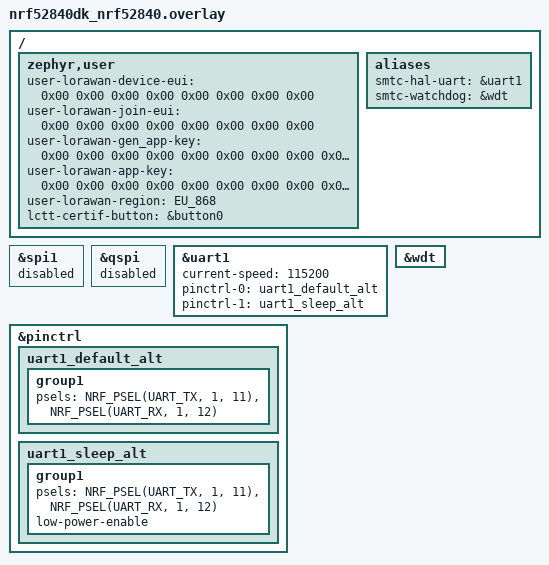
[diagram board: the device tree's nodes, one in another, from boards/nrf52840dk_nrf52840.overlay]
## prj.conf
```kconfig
# Copyright (c) 2024 Semtech Corporation - Félix Piédallu
# SPDX-License-Identifier: Apache-2.0

CONFIG_USE_SEGGER_RTT=n

# ------------------------------ General configuration -------------------------

# required for floorf (which is used within the smtc_modem lib)
CONFIG_NEWLIB_LIBC=y

# stack size (2048 required by Semtech)
CONFIG_MAIN_STACK_SIZE=4096
# some opereations will be triggered from the system workq, so match above stack size
CONFIG_SYSTEM_WORKQUEUE_STACK_SIZE=4096
# heap size
CONFIG_HEAP_MEM_POOL_SIZE=4096

CONFIG_LOG_BUFFER_SIZE=4096

CONFIG_LOG=y
CONFIG_LOG_BACKEND_UART=y

CONFIG_TEST_RANDOM_GENERATOR=y

CONFIG_SERIAL=y
CONFIG_UART_INTERRUPT_DRIVEN=y

# ------------------------------ Transceiver driver ----------------------------
CONFIG_LORA_BASICS_MODEM_DRIVERS=y
CONFIG_LORA_BASICS_MODEM_DRIVERS_EVENT_TRIGGER_GLOBAL_THREAD=y

# ------------------------------ Requirements LBM ------------------------------

CONFIG_SETTINGS=y
CONFIG_SETTINGS_NVS=y

CONFIG_NVS=y
CONFIG_FLASH=y
CONFIG_FLASH_MAP=y

CONFIG_REBOOT=y

# ------------------------------ LoRa Basics Modem -----------------------------

CONFIG_LORA_BASICS_MODEM=y

# FIXME: maybe use SETTINGS
CONFIG_LORA_BASICS_MODEM_USER_STORAGE_IMPL=n

CONFIG_LORA_BASICS_MODEM_RP2_103=y
CONFIG_LORA_BASICS_MODEM_ENABLE_ALL_REGIONS=y

CONFIG_LORA_BASICS_MODEM_CRYPTOGRAPHY_SOFT=n

CONFIG_LORA_BASICS_MODEM_CLASS_B=y
CONFIG_LORA_BASICS_MODEM_CLASS_C=y
CONFIG_LORA_BASICS_MODEM_MULTICAST=y
CONFIG_LORA_BASICS_MODEM_CSMA=y

CONFIG_LORA_BASICS_MODEM_ALC_SYNC=y
CONFIG_LORA_BASICS_MODEM_ALC_SYNC_V2=y

CONFIG_LORA_BASICS_MODEM_FUOTA=y
# CONFIG_LORA_BASICS_MODEM_FUOTA_V1=y
# CONFIG_LORA_BASICS_MODEM_FUOTA_FMP=y
# CONFIG_LORA_BASICS_MODEM_FUOTA_MPA=y

CONFIG_LORA_BASICS_MODEM_ALMANAC=y
CONFIG_LORA_BASICS_MODEM_STREAM=y
CONFIG_LORA_BASICS_MODEM_LFU=y
CONFIG_LORA_BASICS_MODEM_DEVICE_MANAGEMENT=y
CONFIG_LORA_BASICS_MODEM_GEOLOCATION=y
CONFIG_LORA_BASICS_MODEM_STORE_AND_FORWARD=y
# CONFIG_LORA_BASICS_MODEM_BEACON_TX=y
# CONFIG_LORA_BASICS_MODEM_RELAY_TX=y


CONFIG_LORA_BASICS_MODEM_APP_HELPERS=y

# Increase required for store_and_forward
CONFIG_LORA_BASICS_MODEM_CONTEXT_BUFFER_SIZE=1024


# ------------------------------ Debug ------------------------------

# Compiler optimizations will be set to -Og independently of other options.
CONFIG_DEBUG_OPTIMIZATIONS=y

# This option enables the addition of various information that can be
# used by debuggers in debugging the system, or enable additional debugging
# information to be reported at runtime.
CONFIG_DEBUG_INFO=y

# This option adds additional information to the thread object, so that the
# debugger can discover the threads.
CONFIG_DEBUG_THREAD_INFO=y
CONFIG_DEBUG_COREDUMP=y

# enable asserts during development only
CONFIG_ASSERT=y

CONFIG_LORA_BASICS_MODEM_LOG_LEVEL_DBG=y
CONFIG_LORA_BASICS_MODEM_LOG_LEVEL_DEEP_DBG=y

# ------------------------------ Requirements of this sample ------------------------------

CONFIG_PM_DEVICE=y
CONFIG_WATCHDOG=y
```

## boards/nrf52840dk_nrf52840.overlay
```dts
/*
 * Copyright (c) 2024 Semtech Corporation
 *
 * SPDX-License-Identifier: Apache-2.0
 */

/ {
	zephyr,user {
		user-lorawan-device-eui = <0x00 0x00 0x00 0x00 0x00 0x00 0x00 0x00>;
		user-lorawan-join-eui = <0x00 0x00 0x00 0x00 0x00 0x00 0x00 0x00>;
		user-lorawan-gen_app-key = <0x00 0x00 0x00 0x00 0x00 0x00 0x00 0x00 0x00 0x00 0x00 0x00 0x00 0x00 0x00 0x00>;
		user-lorawan-app-key = <0x00 0x00 0x00 0x00 0x00 0x00 0x00 0x00 0x00 0x00 0x00 0x00 0x00 0x00 0x00 0x00>;
		user-lorawan-region = "EU_868";

		/* PINS used for the sample. */
		lctt-certif-button = &button0;
	};

	aliases {
		/* Specify which UART is used as input for the hw modem tester */
		smtc-hal-uart = &uart1;
		smtc-watchdog = &wdt;
	};
};

&spi1 {
	status = "disabled";
};
// &spi2 {
//     status = "disabled";
// };
&qspi {
	status = "disabled";
};

/* Specify which UART is used as input for the hw modem tester */
&uart1 {
	status = "okay";

	current-speed = <115200>;

	pinctrl-0 = <&uart1_default_alt>;
	pinctrl-1 = <&uart1_sleep_alt>;
	pinctrl-names = "default", "sleep";
	/delete-property/ hw-flow-control;
};

&pinctrl {
	uart1_default_alt: uart1_default_alt {
		group1 {
			psels = <NRF_PSEL(UART_TX, 1, 11)>, <NRF_PSEL(UART_RX, 1, 12)>;
		};
	};

	uart1_sleep_alt: uart1_sleep_alt {
		group1 {
			psels = <NRF_PSEL(UART_TX, 1, 11)>, <NRF_PSEL(UART_RX, 1, 12)>;
			low-power-enable;
		};
	};
};

&wdt {
	status = "okay";
};
```

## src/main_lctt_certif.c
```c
/*
 * Copyright (c) 2024 Semtech Corporation
 *
 * SPDX-License-Identifier: Apache-2.0
 */

#include <zephyr/kernel.h>
#include <stdint.h>
#include <stdbool.h>

#include "smtc_modem_api.h"
#include "smtc_modem_utilities.h"

#include "smtc_modem_hal.h"
#include "smtc_hal_dbg_trace.h"

#include "smtc_hal_mcu.h"
#include "smtc_hal_gpio.h"
#include "smtc_hal_watchdog.h"
#include <smtc_modem_hal_init.h>

#include <string.h>
#include "smtc_modem_relay_api.h"

/*!
 * @brief Stringify constants
 */
#define xstr(a) str(a)
#define str(a)  #a

/*!
 * @brief Helper macro that returned a human-friendly message if a command does not return
 * SMTC_MODEM_RC_OK
 *
 * @remark The macro is implemented to be used with functions returning a @ref
 * smtc_modem_return_code_t
 *
 * @param[in] rc  Return code
 */

#define ASSERT_SMTC_MODEM_RC(rc_func)                                                              \
	do {                                                                                       \
		smtc_modem_return_code_t rc = rc_func;                                             \
		if (rc == SMTC_MODEM_RC_NOT_INIT) {                                                \
			SMTC_HAL_TRACE_ERROR("In %s - %s (line %d): %s\n", __FILE__, __func__,     \
					     __LINE__, xstr(SMTC_MODEM_RC_NOT_INIT));              \
		} else if (rc == SMTC_MODEM_RC_INVALID) {                                          \
			SMTC_HAL_TRACE_ERROR("In %s - %s (line %d): %s\n", __FILE__, __func__,     \
					     __LINE__, xstr(SMTC_MODEM_RC_INVALID));               \
		} else if (rc == SMTC_MODEM_RC_BUSY) {                                             \
			SMTC_HAL_TRACE_ERROR("In %s - %s (line %d): %s\n", __FILE__, __func__,     \
					     __LINE__, xstr(SMTC_MODEM_RC_BUSY));                  \
		} else if (rc == SMTC_MODEM_RC_FAIL) {                                             \
			SMTC_HAL_TRACE_ERROR("In %s - %s (line %d): %s\n", __FILE__, __func__,     \
					     __LINE__, xstr(SMTC_MODEM_RC_FAIL));                  \
		} else if (rc == SMTC_MODEM_RC_NO_TIME) {                                          \
			SMTC_HAL_TRACE_WARNING("In %s - %s (line %d): %s\n", __FILE__, __func__,   \
					       __LINE__, xstr(SMTC_MODEM_RC_NO_TIME));             \
		} else if (rc == SMTC_MODEM_RC_INVALID_STACK_ID) {                                 \
			SMTC_HAL_TRACE_ERROR("In %s - %s (line %d): %s\n", __FILE__, __func__,     \
					     __LINE__, xstr(SMTC_MODEM_RC_INVALID_STACK_ID));      \
		} else if (rc == SMTC_MODEM_RC_NO_EVENT) {                                         \
			SMTC_HAL_TRACE_INFO("In %s - %s (line %d): %s\n", __FILE__, __func__,      \
					    __LINE__, xstr(SMTC_MODEM_RC_NO_EVENT));               \
		}                                                                                  \
	} while (0)

/*
 * -----------------------------------------------------------------------------
 * --- PRIVATE CONSTANTS -------------------------------------------------------
 */

/* lr11xx radio context and its use in the ralf layer */
static const struct device *transceiver = DEVICE_DT_GET(DT_ALIAS(lora_transceiver));

/**
 * Stack id value (multistacks modem is not yet available)
 */
#define STACK_ID 0

/**
 * @brief Stack credentials
 */
#if !defined(USE_LR11XX_CREDENTIALS)
static const uint8_t user_dev_eui[8] = DT_PROP(DT_PATH(zephyr_user), user_lorawan_device_eui);
static const uint8_t user_join_eui[8] = DT_PROP(DT_PATH(zephyr_user), user_lorawan_join_eui);
static const uint8_t user_gen_app_key[16] = DT_PROP(DT_PATH(zephyr_user), user_lorawan_gen_app_key);
static const uint8_t user_app_key[16] = DT_PROP(DT_PATH(zephyr_user), user_lorawan_app_key);
#endif

#define DT_MODEM_REGION(region) DT_CAT(SMTC_MODEM_REGION_, region)
#define MODEM_REGION DT_MODEM_REGION(DT_STRING_UNQUOTED(DT_PATH(zephyr_user), user_lorawan_region))

/**
 * @brief Watchdog counter reload value during sleep (The period must be lower than MCU watchdog
 * period (here 32s))
 */
#define WATCHDOG_RELOAD_PERIOD_MS 20000

/**
 * @brief Periodical uplink alarm delay in seconds
 */
#define PERIODICAL_UPLINK_DELAY_S 10

#define USER_BUTTON_NODE DT_PROP(DT_PATH(zephyr_user), lctt_certif_button)
#if !DT_NODE_HAS_STATUS(USER_BUTTON_NODE, okay)
#error "Unsupported board: lctt-certif-button devicetree alias is not defined"
#endif
static const struct gpio_dt_spec button = GPIO_DT_SPEC_GET_OR(USER_BUTTON_NODE, gpios, {0});
static struct gpio_callback button_cb_data;

/*
 * -----------------------------------------------------------------------------
 * --- PRIVATE TYPES -----------------------------------------------------------
 */

/*
 * -----------------------------------------------------------------------------
 * --- PRIVATE VARIABLES -------------------------------------------------------
 */
/* Buffer for rx payload */
static uint8_t rx_payload[SMTC_MODEM_MAX_LORAWAN_PAYLOAD_LENGTH] = {0};
/* Size of the payload in the rx_payload buffer */
static uint8_t rx_payload_size;
/* Metadata of downlink */
static smtc_modem_dl_metadata_t rx_metadata = {0};
/* Remaining downlink payload in modem */
static uint8_t rx_remaining;

/* Flag for button status */
static volatile bool user_button_is_press;
/* uplink raising counter */
static uint32_t uplink_counter;

static bool certif_running;

/**
 * @brief Internal credentials
 */
#if defined(USE_LR11XX_CREDENTIALS)
static uint8_t chip_eui[SMTC_MODEM_EUI_LENGTH] = {0};
static uint8_t chip_pin[SMTC_MODEM_PIN_LENGTH] = {0};
#endif
/*
 * -----------------------------------------------------------------------------
 * --- PRIVATE FUNCTIONS DECLARATION -------------------------------------------
 */

/**
 * @brief User callback for modem event
 *
 *  This callback is called every time an event (see smtc_modem_event_t) appears in the modem.
 *  Several events may have to be read from the modem when this callback is called.
 */
static void modem_event_callback(void);

/**
 * @brief User callback for button EXTI
 *
 * @param context Define by the user at the init
 */
static void user_button_callback(void *context);

/**
 * @brief Handle action taken if button is pushed
 *
 */
static void main_handle_push_button(void);

/**
 * @brief Send the 32bits uplink counter on chosen port
 */
static void send_uplink_counter_on_port(uint8_t port);

/*
 * -----------------------------------------------------------------------------
 * --- PUBLIC FUNCTIONS DEFINITION ---------------------------------------------
 */

/* Callbacks for HAL implementation */
static struct smtc_modem_hal_cb prv_hal_cb;

/**
 * @brief Callback for modem hal
 */
static int prv_get_battery_level_cb(uint32_t *value)
{
	*value = 98;
	return 0;
}

/**
 * @brief Callback for modem hal
 */
static int prv_get_temperature_cb(int32_t *value)
{
	*value = 25;
	return 0;
}

/**
 * @brief Callback for modem hal
 */
static int prv_get_voltage_cb(uint32_t *value)
{
	*value = 3300;
	return 0;
}

#ifdef CONFIG_LORA_BASICS_MODEM_FUOTA
static int prv_get_hw_version_for_fuota(uint32_t *version)
{
	*version = 1;
	return 0;
}

static int prv_get_fw_version_for_fuota(uint32_t *version)
{
	*version = 1;
	return 0;
}

static int prv_get_fw_status_available_for_fuota(uint8_t *status)
{
	*status = 1;
	return 0;
}

static int prv_get_next_fw_version_for_fuota(uint32_t *version)
{
	*version = 1;
	return 0;
}

static int prv_get_fw_delete_status_for_fuota(uint32_t status)
{
	return 0;
}
#endif /* CONFIG_LORA_BASICS_MODEM_FUOTA */

/* for zephyr compat*/
void button_pressed(const struct device *dev, struct gpio_callback *cb, uint32_t pins)
{
	user_button_callback(dev);
}
/**
 * @brief Example enable/disable certification mode by pushing blue button
 *
 */
#if defined(USE_RELAY_TX)
static smtc_modem_relay_tx_config_t relay_config = {0};
#endif
int main(void)
{
	uint32_t sleep_time_ms = 0;
	int ret;

	/* Create callback structure for HAL impl */
	prv_hal_cb = (struct smtc_modem_hal_cb){
		.get_battery_level = prv_get_battery_level_cb,
		.get_temperature = prv_get_temperature_cb,
		.get_voltage = prv_get_voltage_cb,

#ifdef CONFIG_LORA_BASICS_MODEM_FUOTA
		.get_hw_version_for_fuota = prv_get_hw_version_for_fuota,
		.get_fw_version_for_fuota = prv_get_fw_version_for_fuota,
		.get_fw_status_available_for_fuota = prv_get_fw_status_available_for_fuota,
		.get_next_fw_version_for_fuota = prv_get_next_fw_version_for_fuota,
		.get_fw_delete_status_for_fuota = prv_get_fw_delete_status_for_fuota,
#endif /* CONFIG_LORA_BASICS_MODEM_FUOTA */
	};

	smtc_modem_hal_init(transceiver);
	smtc_modem_hal_register_callbacks(&prv_hal_cb);
	smtc_modem_set_radio_context(transceiver);

	/* Disable IRQ to avoid unwanted behavior during init */
	hal_mcu_disable_irq();

	/* Configure all the µC periph (clock, gpio, timer, ...) */
	hal_mcu_init();

	/* Init the modem and use modem_event_callback as event callback, please
	 * note that the callback will be called immediately after the first call to
	 * smtc_modem_run_engine because of the reset detection
	 */
	smtc_modem_init(&modem_event_callback);

	/* Configure Nucleo blue button as EXTI */
	if (!gpio_is_ready_dt(&button)) {
		printk("Error: button device %s is not ready\n", button.port->name);
		return 1;
	}
	ret = gpio_pin_configure_dt(&button, GPIO_INPUT);
	if (ret != 0) {
		printk("Error %d: failed to configure %s pin %d\n", ret, button.port->name,
		       button.pin);
		return 1;
	}
	ret = gpio_pin_interrupt_configure_dt(&button, GPIO_INT_EDGE_TO_INACTIVE);
	if (ret != 0) {
		printk("Error %d: failed to configure interrupt on %s pin %d\n", ret,
		       button.port->name, button.pin);
		return 1;
	}
	gpio_init_callback(&button_cb_data, button_pressed, BIT(button.pin));
	gpio_add_callback(button.port, &button_cb_data);

	/* Init done: enable interruption */
	hal_mcu_enable_irq();

	SMTC_HAL_TRACE_INFO("Certification example is starting\n");
	SMTC_HAL_TRACE_INFO("Push button to enable/disable certification\n");

	while (1) {
		/* Check button */
		if (user_button_is_press) {
			user_button_is_press = false;

			main_handle_push_button();
		}

		/* Modem process launch */
		sleep_time_ms = smtc_modem_run_engine();

		/* Atomically check sleep conditions (button was not pressed) */
		hal_mcu_disable_irq();
		if (!user_button_is_press && !smtc_modem_is_irq_flag_pending()) {
			/* hal_watchdog_reload(); */
			uint32_t real_sleep_time_ms = MIN(sleep_time_ms, WATCHDOG_RELOAD_PERIOD_MS);

			/* LOG_INF("Sleeping for %d ms", real_sleep_time_ms); */
			/* hal_mcu_set_sleep_for_ms(real_sleep_time_ms); */
			/* real_sleep_time_ms = 1; */
			smtc_modem_hal_interruptible_msleep(K_MSEC(real_sleep_time_ms));
		}
		/* hal_watchdog_reload(); */
		hal_mcu_enable_irq();
	}
	return 0;
}

/*
 * -----------------------------------------------------------------------------
 * --- PRIVATE FUNCTIONS DEFINITION --------------------------------------------
 */

static void modem_event_callback(void)
{
	SMTC_HAL_TRACE_MSG("Modem event callback\n");

	smtc_modem_event_t current_event;
	uint8_t event_pending_count;
	uint8_t stack_id = STACK_ID;

	/* Continue to read modem event until all event has been processed */
	do {
		/* Read modem event */
		ASSERT_SMTC_MODEM_RC(smtc_modem_get_event(&current_event, &event_pending_count));

		switch (current_event.event_type) {
		case SMTC_MODEM_EVENT_RESET: {
			SMTC_HAL_TRACE_INFO("Event received: RESET\n");

#if !defined(USE_LR11XX_CREDENTIALS)
			/* Set user credentials */
			ASSERT_SMTC_MODEM_RC(smtc_modem_set_deveui(stack_id, user_dev_eui));
			ASSERT_SMTC_MODEM_RC(smtc_modem_set_joineui(stack_id, user_join_eui));
			ASSERT_SMTC_MODEM_RC(smtc_modem_set_appkey(stack_id, user_gen_app_key));
			ASSERT_SMTC_MODEM_RC(smtc_modem_set_nwkkey(stack_id, user_app_key));
#else
			/* Get internal credentials */
			ASSERT_SMTC_MODEM_RC(smtc_modem_get_chip_eui(stack_id, chip_eui));
			SMTC_HAL_TRACE_ARRAY("CHIP_EUI", chip_eui, SMTC_MODEM_EUI_LENGTH);
			ASSERT_SMTC_MODEM_RC(smtc_modem_get_pin(stack_id, chip_pin));
			SMTC_HAL_TRACE_ARRAY("CHIP_PIN", chip_pin, SMTC_MODEM_PIN_LENGTH);
#endif
			/* Set user region */
			ASSERT_SMTC_MODEM_RC(smtc_modem_set_region(stack_id, MODEM_REGION));
#if defined(USE_RELAY_TX)
			relay_config.second_ch_enable = false;
			relay_config.activation = SMTC_MODEM_RELAY_TX_ACTIVATION_MODE_ED_CONTROLED;
			relay_config.number_of_miss_wor_ack_to_switch_in_nosync_mode = 1;
			relay_config.smart_level = 5;
			relay_config.backoff = 4;
			ASSERT_SMTC_MODEM_RC(smtc_modem_relay_tx_enable(stack_id, &relay_config));
#endif
			ASSERT_SMTC_MODEM_RC(
				smtc_modem_get_certification_mode(stack_id, &certif_running));
			if (!certif_running) {
				ASSERT_SMTC_MODEM_RC(smtc_modem_join_network(stack_id));
			}
			break;
		}
		case SMTC_MODEM_EVENT_ALARM:
			SMTC_HAL_TRACE_INFO("Event received: ALARM\n");
			if (certif_running) {
				ASSERT_SMTC_MODEM_RC(smtc_modem_alarm_clear_timer());
			} else {
				/* Send periodical uplink on port 101 */
				send_uplink_counter_on_port(101);
				ASSERT_SMTC_MODEM_RC(
					smtc_modem_alarm_start_timer(PERIODICAL_UPLINK_DELAY_S));
			}
			break;

		case SMTC_MODEM_EVENT_JOINED:
			SMTC_HAL_TRACE_INFO("Event received: JOINED\n");
			SMTC_HAL_TRACE_INFO("Modem is now joined\n");

			if (!certif_running) {
				/* start periodical uplink alarm */
				ASSERT_SMTC_MODEM_RC(
					smtc_modem_alarm_start_timer(PERIODICAL_UPLINK_DELAY_S));
			}
			break;

		case SMTC_MODEM_EVENT_TXDONE:
			SMTC_HAL_TRACE_INFO("Event received: TXDONE\n");
			SMTC_HAL_TRACE_INFO("Transmission done\n");
			break;

		case SMTC_MODEM_EVENT_DOWNDATA:
			SMTC_HAL_TRACE_INFO("Event received: DOWNDATA\n");
			/* Get downlink data */
			ASSERT_SMTC_MODEM_RC(smtc_modem_get_downlink_data(
				rx_payload, &rx_payload_size, &rx_metadata, &rx_remaining));
			SMTC_HAL_TRACE_PRINTF("Data received on port %u\n", rx_metadata.fport);
			SMTC_HAL_TRACE_ARRAY("Received payload", rx_payload, rx_payload_size);
			break;

		case SMTC_MODEM_EVENT_JOINFAIL:
			SMTC_HAL_TRACE_INFO("Event received: JOINFAIL\n");
			break;

		case SMTC_MODEM_EVENT_ALCSYNC_TIME:
			SMTC_HAL_TRACE_INFO("Event received: ALCSync service TIME\n");
			break;

		case SMTC_MODEM_EVENT_LINK_CHECK:
			SMTC_HAL_TRACE_INFO("Event received: LINK_CHECK\n");
			break;

		case SMTC_MODEM_EVENT_CLASS_B_PING_SLOT_INFO:
			SMTC_HAL_TRACE_INFO("Event received: CLASS_B_PING_SLOT_INFO\n");
			break;

		case SMTC_MODEM_EVENT_CLASS_B_STATUS:
			SMTC_HAL_TRACE_INFO("Event received: CLASS_B_STATUS\n");
			break;

		case SMTC_MODEM_EVENT_LORAWAN_MAC_TIME:
			SMTC_HAL_TRACE_WARNING("Event received: LORAWAN MAC TIME\n");
			break;

		case SMTC_MODEM_EVENT_LORAWAN_FUOTA_DONE: {
			bool status = current_event.event_data.fuota_status.successful;

			if (status) {
				SMTC_HAL_TRACE_INFO("Event received: FUOTA SUCCESSFUL\n");
			} else {
				SMTC_HAL_TRACE_WARNING("Event received: FUOTA FAIL\n");
			}
			break;
		}

		case SMTC_MODEM_EVENT_NO_MORE_MULTICAST_SESSION_CLASS_C:
			SMTC_HAL_TRACE_INFO("Event received: MULTICAST CLASS_C STOP\n");
			break;

		case SMTC_MODEM_EVENT_NO_MORE_MULTICAST_SESSION_CLASS_B:
			SMTC_HAL_TRACE_INFO("Event received: MULTICAST CLASS_B STOP\n");
			break;

		case SMTC_MODEM_EVENT_NEW_MULTICAST_SESSION_CLASS_C:
			SMTC_HAL_TRACE_INFO("Event received: New MULTICAST CLASS_C\n");
			break;

		case SMTC_MODEM_EVENT_NEW_MULTICAST_SESSION_CLASS_B:
			SMTC_HAL_TRACE_INFO("Event received: New MULTICAST CLASS_B\n");
			break;

		case SMTC_MODEM_EVENT_FIRMWARE_MANAGEMENT:
			SMTC_HAL_TRACE_INFO("Event received: FIRMWARE_MANAGEMENT\n");
			if (current_event.event_data.fmp.status ==
			    SMTC_MODEM_EVENT_FMP_REBOOT_IMMEDIATELY) {
				smtc_modem_hal_reset_mcu();
			}
			break;

		case SMTC_MODEM_EVENT_STREAM_DONE:
			SMTC_HAL_TRACE_INFO("Event received: STREAM_DONE\n");
			break;

		case SMTC_MODEM_EVENT_UPLOAD_DONE:
			SMTC_HAL_TRACE_INFO("Event received: UPLOAD_DONE\n");
			break;

		case SMTC_MODEM_EVENT_DM_SET_CONF:
			SMTC_HAL_TRACE_INFO("Event received: DM_SET_CONF\n");
			break;

		case SMTC_MODEM_EVENT_MUTE:
			SMTC_HAL_TRACE_INFO("Event received: MUTE\n");
			break;

		default:
			SMTC_HAL_TRACE_ERROR("Unknown event %u\n", current_event.event_type);
			break;
		}
	} while (event_pending_count > 0);
}

static void user_button_callback(void *context)
{
	SMTC_HAL_TRACE_INFO("Button pushed\n");

	(void)context; /* Not used in the example - avoid warning */

	static uint32_t last_press_timestamp_ms;

	/* Debounce the button press, avoid multiple triggers */
	if ((int32_t)(smtc_modem_hal_get_time_in_ms() - last_press_timestamp_ms) > 500) {
		last_press_timestamp_ms = smtc_modem_hal_get_time_in_ms();
		user_button_is_press = true;
	}
}
static void main_handle_push_button(void)
{
	if (certif_running) {
		smtc_modem_set_certification_mode(STACK_ID, false);
		ASSERT_SMTC_MODEM_RC(smtc_modem_leave_network(STACK_ID));
		ASSERT_SMTC_MODEM_RC(smtc_modem_join_network(STACK_ID));
		certif_running = false;
	} else {
		smtc_modem_set_certification_mode(STACK_ID, true);
		certif_running = true;
	}
}

static void send_uplink_counter_on_port(uint8_t port)
{
	/* Send uplink counter on port 102 */
	uint8_t buff[4] = {0};

	buff[0] = (uplink_counter >> 24) & 0xFF;
	buff[1] = (uplink_counter >> 16) & 0xFF;
	buff[2] = (uplink_counter >> 8) & 0xFF;
	buff[3] = (uplink_counter & 0xFF);
	ASSERT_SMTC_MODEM_RC(smtc_modem_request_uplink(STACK_ID, port, false, buff, 4));
	/* Increment uplink counter */
	uplink_counter++;
}

/* --- EOF ------------------------------------------------------------------ */
```
